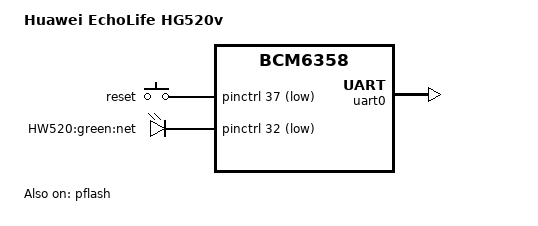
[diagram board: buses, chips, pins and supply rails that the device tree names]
/dts-v1/;

#include "bcm6358.dtsi"

#include <dt-bindings/input/input.h>

/ {
	model = "Huawei EchoLife HG520v";
	compatible = "huawei,hg520v", "brcm,bcm6358";

	chosen {
		bootargs = "rootfstype=squashfs,jffs2 noinitrd console=ttyS0,115200";
		stdout-path = "serial0:115200n8";
	};

	keys {
		compatible = "gpio-keys-polled";
		#address-cells = <1>;
		#size-cells = <0>;
		poll-interval = <20>;

		reset {
			label = "reset";
			gpios = <&pinctrl 37 1>;
			linux,code = <KEY_RESTART>;
			debounce-interval = <60>;
		};
	};

	leds {
		compatible = "gpio-leds";

		inet_green {
			label = "HW520:green:net";
			gpios = <&pinctrl 32 1>;
		};
	};
};

&pflash {
	status = "ok";

	partitions {
		compatible = "fixed-partitions";
		#address-cells = <1>;
		#size-cells = <1>;

		cfe@0 {
			label = "CFE";
			reg = <0x000000 0x010000>;
			read-only;
		};

		linux@10000 {
			label = "linux";
			reg = <0x010000 0x3e0000>;
			compatible = "brcm,bcm963xx-imagetag";
		};

		nvram@3f0000 {
			label = "nvram";
			reg = <0x3f0000 0x010000>;
		};
	};
};

&uart0 {
	status = "ok";
};
